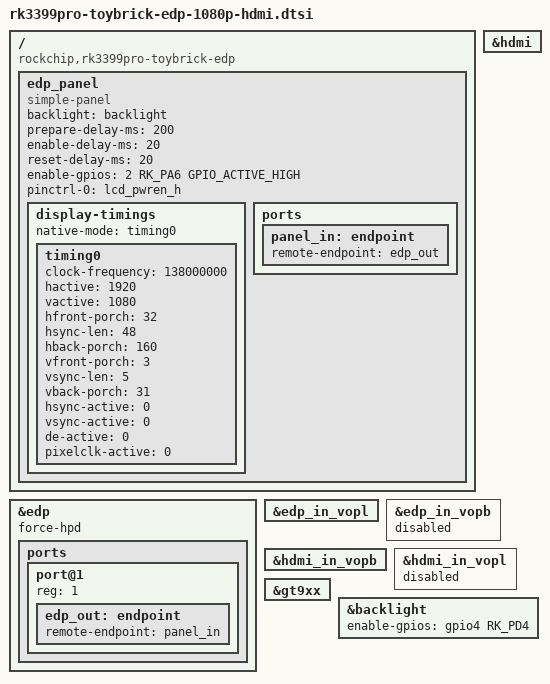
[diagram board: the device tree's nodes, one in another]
/*
 * Copyright (c) 2019 Fuzhou Rockchip Electronics Co., Ltd
 *
 * This file is dual-licensed: you can use it either under the terms
 * of the GPL or the X11 license, at your option. Note that this dual
 * licensing only applies to this file, and not this project as a
 * whole.
 *
 *  a) This file is free software; you can redistribute it and/or
 *     modify it under the terms of the GNU General Public License as
 *     published by the Free Software Foundation; either version 2 of the
 *     License, or (at your option) any later version.
 *
 *     This file is distributed in the hope that it will be useful,
 *     but WITHOUT ANY WARRANTY; without even the implied warranty of
 *     MERCHANTABILITY or FITNESS FOR A PARTICULAR PURPOSE.  See the
 *     GNU General Public License for more details.
 *
 * Or, alternatively,
 *
 *  b) Permission is hereby granted, free of charge, to any person
 *     obtaining a copy of this software and associated documentation
 *     files (the "Software"), to deal in the Software without
 *     restriction, including without limitation the rights to use,
 *     copy, modify, merge, publish, distribute, sublicense, and/or
 *     sell copies of the Software, and to permit persons to whom the
 *     Software is furnished to do so, subject to the following
 *     conditions:
 *
 *     The above copyright notice and this permission notice shall be
 *     included in all copies or substantial portions of the Software.
 *
 *     THE SOFTWARE IS PROVIDED "AS IS", WITHOUT WARRANTY OF ANY KIND,
 *     EXPRESS OR IMPLIED, INCLUDING BUT NOT LIMITED TO THE WARRANTIES
 *     OF MERCHANTABILITY, FITNESS FOR A PARTICULAR PURPOSE AND
 *     NONINFRINGEMENT. IN NO EVENT SHALL THE AUTHORS OR COPYRIGHT
 *     HOLDERS BE LIABLE FOR ANY CLAIM, DAMAGES OR OTHER LIABILITY,
 *     WHETHER IN AN ACTION OF CONTRACT, TORT OR OTHERWISE, ARISING
 *     FROM, OUT OF OR IN CONNECTION WITH THE SOFTWARE OR THE USE OR
 *     OTHER DEALINGS IN THE SOFTWARE.
 */

/ {
	compatible = "rockchip,rk3399pro-toybrick-edp", "rockchip,rk3399pro";

	edp_panel: edp_panel {
		compatible = "simple-panel";
		backlight = <&backlight>;
		prepare-delay-ms = <200>;
		enable-delay-ms = <20>;
		reset-delay-ms = <20>;
		enable-gpios = <2 RK_PA6 GPIO_ACTIVE_HIGH>;
		pinctrl-names = "default";
		pinctrl-0 = <&lcd_pwren_h>;
		display-timings {
			native-mode = <&timing0>;

			timing0: timing0 {
				clock-frequency = <138000000>;
				hactive = <1920>;
				vactive = <1080>;
				hfront-porch = <32>;
				hsync-len = <48>;
				hback-porch = <160>;
				vfront-porch = <3>;
				vsync-len = <5>;
				vback-porch = <31>;
				hsync-active = <0>;
				vsync-active = <0>;
				de-active = <0>;
				pixelclk-active = <0>;
			};
		};

		ports {
			panel_in: endpoint {
				remote-endpoint = <&edp_out>;
			};
		};
	};
};

&edp {
	status = "okay";
	force-hpd;

	ports {
		port@1 {
			reg = <1>;

			edp_out: endpoint {
				remote-endpoint = <&panel_in>;
			};
		};
	};
};

&hdmi {
    status = "okay";
};

&edp_in_vopl {
	status = "okay";
};

&edp_in_vopb {
	status = "disabled";
};

&hdmi_in_vopb {
	status = "okay";
};

&hdmi_in_vopl {
	status = "disabled";
};

&gt9xx {
	status = "okay";
};

&backlight {
	status = "okay";
	enable-gpios = <&gpio4 RK_PD4 GPIO_ACTIVE_HIGH>;
};
